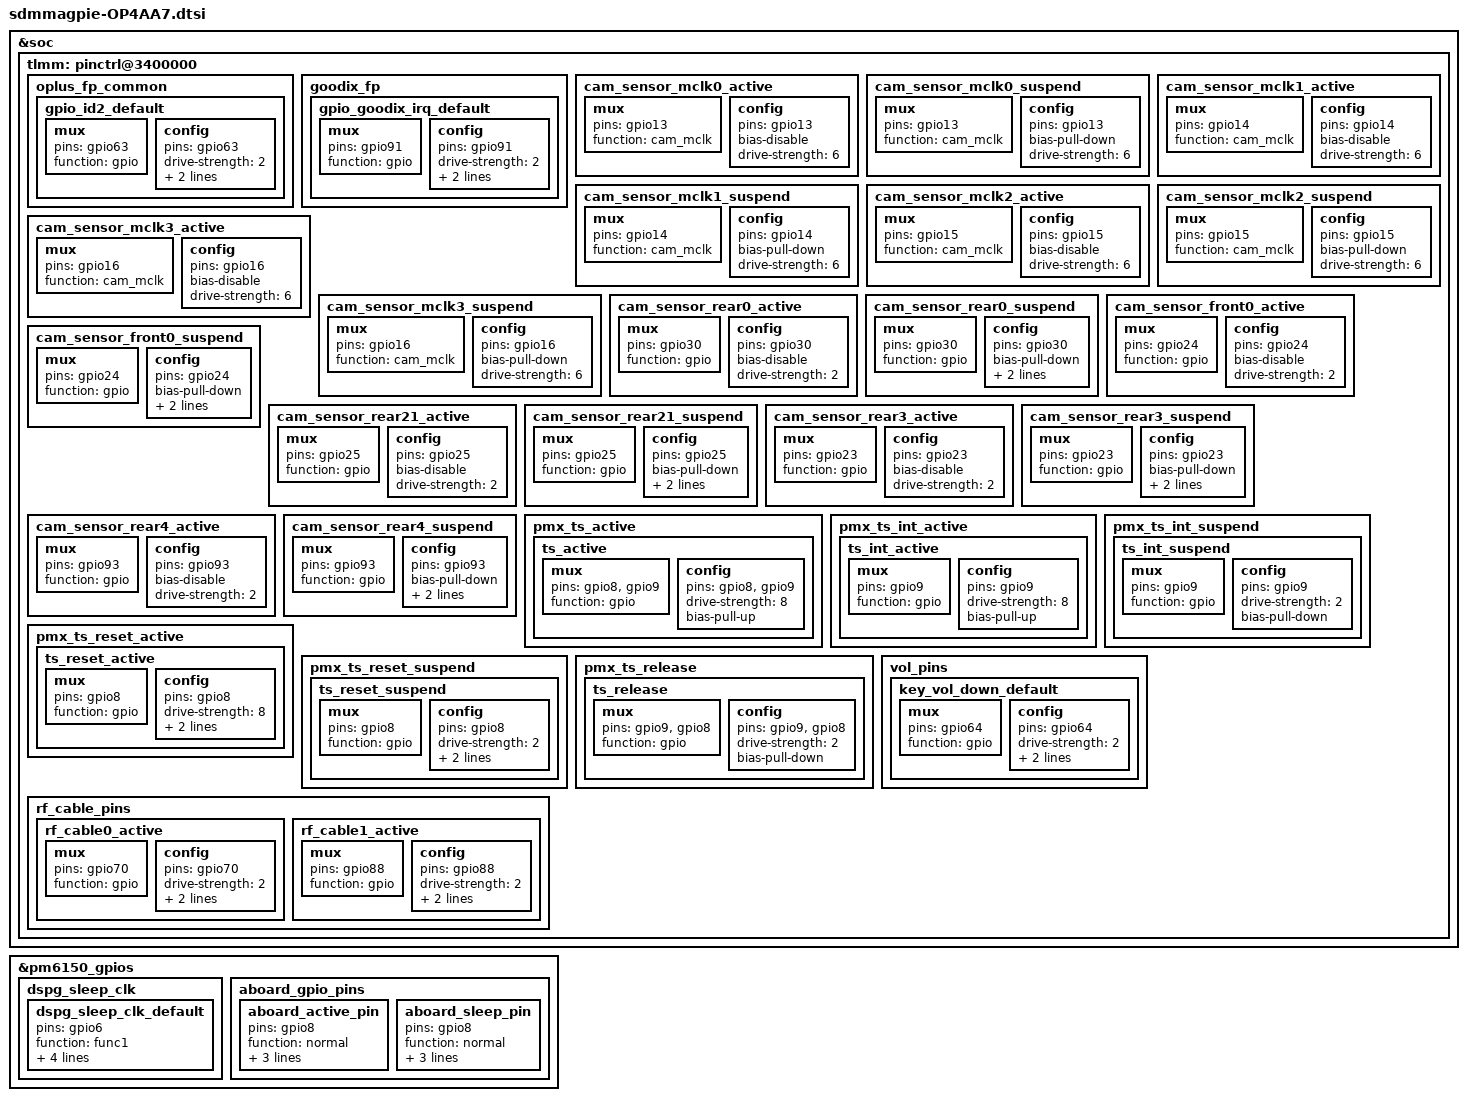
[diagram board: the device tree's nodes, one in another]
/* Copyright (c) 2018-2019, The Linux Foundation. All rights reserved.
 *
 * This program is free software; you can redistribute it and/or modify
 * it under the terms of the GNU General Public License version 2 and
 * only version 2 as published by the Free Software Foundation.
 *
 * This program is distributed in the hope that it will be useful,
 * but WITHOUT ANY WARRANTY; without even the implied warranty of
 * MERCHANTABILITY or FITNESS FOR A PARTICULAR PURPOSE.  See the
 * GNU General Public License for more details.
 */
#include <dt-bindings/gpio/gpio.h>
#include <dt-bindings/pinctrl/qcom,pmic-gpio.h>

&soc {
	tlmm: pinctrl@3400000 {
		oplus_fp_common{
			gpio_id2_default: gpio_id2_default {
				mux {
					pins = "gpio63";
					function = "gpio";
				};
				config {
					pins = "gpio63";
					drive-strength = <2>;
					bias-disable;
					input-enable;
				};
			};
		};

		goodix_fp{
			gpio_goodix_irq_default: gpio_goodix_irq_default {
				mux {
					pins = "gpio91";
					function = "gpio";
				};
				config {
					pins = "gpio91";
					drive-strength = <2>;
					bias-disable;
					input-enable;
				};
			};
		};

		cam_sensor_mclk0_active: cam_sensor_mclk0_active {
			/* MCLK0 */
			mux {
				pins = "gpio13";
				function = "cam_mclk";
			};

			config {
				pins = "gpio13";
				bias-disable; /* No PULL */
				drive-strength = <6>; /* 6 MA */
			};
		};

		cam_sensor_mclk0_suspend: cam_sensor_mclk0_suspend {
			/* MCLK0 */
			mux {
				pins = "gpio13";
				function = "cam_mclk";
			};

			config {
				pins = "gpio13";
				bias-pull-down; /* PULL DOWN */
				drive-strength = <6>; /* 6 MA */
			};
		};

		cam_sensor_mclk1_active: cam_sensor_mclk1_active {
			/* MCLK1 */
			mux {
				pins = "gpio14";
				function = "cam_mclk";
			};

			config {
				pins = "gpio14";
				bias-disable; /* No PULL */
				drive-strength = <6>; /* 6 MA */
			};
		};

		cam_sensor_mclk1_suspend: cam_sensor_mclk1_suspend {
			/* MCLK1 */
			mux {
				pins = "gpio14";
				function = "cam_mclk";
			};

			config {
				pins = "gpio14";
				bias-pull-down; /* PULL DOWN */
				drive-strength = <6>; /* 6 MA */
			};
		};

		cam_sensor_mclk2_active: cam_sensor_mclk2_active {
			/* MCLK2 */
			mux {
				pins = "gpio15";
				function = "cam_mclk";
			};

			config {
				pins = "gpio15";
				bias-disable; /* No PULL */
				drive-strength = <6>; /* 6 MA */
			};
		};

		cam_sensor_mclk2_suspend: cam_sensor_mclk2_suspend {
			/* MCLK2 */
			mux {
				pins = "gpio15";
				function = "cam_mclk";
			};

			config {
				pins = "gpio15";
				bias-pull-down; /* PULL DOWN */
				drive-strength = <6>; /* 6 MA */
			};
		};

		cam_sensor_mclk3_active: cam_sensor_mclk3_active {
			/* MCLK3 */
			mux {
				pins = "gpio16";
				function = "cam_mclk";
			};

			config {
				pins = "gpio16";
				bias-disable; /* No PULL */
				drive-strength = <6>; /* 6 MA */
			};
		};

		cam_sensor_mclk3_suspend: cam_sensor_mclk3_suspend {
			/* MCLK3 */
			mux {
				pins = "gpio16";
				function = "cam_mclk";
			};

			config {
				pins = "gpio16";
				bias-pull-down; /* PULL DOWN */
				drive-strength = <6>; /* 6 MA */
			};
		};
		cam_sensor_rear0_active: cam_sensor_rear0_active {
			/* RESET */
			mux {
				pins = "gpio30";
				function = "gpio";
			};

			config {
				pins = "gpio30";
				bias-disable; /* No PULL */
				drive-strength = <2>; /* 2 MA */
			};
		};

		cam_sensor_rear0_suspend: cam_sensor_rear0_suspend {
			/* RESET */
			mux {
				pins = "gpio30";
				function = "gpio";
			};

			config {
				pins = "gpio30";
				bias-pull-down; /* PULL DOWN */
				drive-strength = <2>; /* 2 MA */
				output-low;
			};
		};

		cam_sensor_front0_active: cam_sensor_front0_active {
			/* RESET  */
			mux {
				pins = "gpio24";
				function = "gpio";
			};

			config {
				pins = "gpio24";
				bias-disable; /* No PULL */
				drive-strength = <2>; /* 2 MA */
			};
		};

		cam_sensor_front0_suspend: cam_sensor_front0_suspend {
			/* RESET */
			mux {
				pins = "gpio24";
				function = "gpio";
			};

			config {
				pins = "gpio24";
				bias-pull-down; /* PULL DOWN */
				drive-strength = <2>; /* 2 MA */
				output-low;
			};
		};
		cam_sensor_rear21_active: cam_sensor_rear21_active {
			/* RESET */
			mux {
				pins = "gpio25";
				function = "gpio";
			};

			config {
				pins = "gpio25";
				bias-disable; /* No PULL */
				drive-strength = <2>; /* 2 MA */
			};
		};

		cam_sensor_rear21_suspend: cam_sensor_rear21_suspend {
			/* RESET */
			mux {
				pins = "gpio25";
				function = "gpio";
			};

			config {
				pins = "gpio25";
				bias-pull-down; /* PULL DOWN */
				drive-strength = <2>; /* 2 MA */
				output-low;
			};
		};
		cam_sensor_rear3_active: cam_sensor_rear3_active {
			/* RESET  */
			mux {
				pins = "gpio23";
				function = "gpio";
			};

			config {
				pins = "gpio23";
				bias-disable; /* No PULL */
				drive-strength = <2>; /* 2 MA */
			};
		};

		cam_sensor_rear3_suspend: cam_sensor_rear3_suspend {
			/* RESET */
			mux {
				pins = "gpio23";
				function = "gpio";
			};

			config {
				pins = "gpio23";
				bias-pull-down; /* PULL DOWN */
				drive-strength = <2>; /* 2 MA */
				output-low;
			};
		};
		cam_sensor_rear4_active: cam_sensor_rear4_active {
			/* RESET  */
			mux {
				pins = "gpio93";
				function = "gpio";
			};

			config {
				pins = "gpio93";
				bias-disable; /* No PULL */
				drive-strength = <2>; /* 2 MA */
			};
		};

		cam_sensor_rear4_suspend: cam_sensor_rear4_suspend {
			/* RESET */
			mux {
				pins = "gpio93";
				function = "gpio";
			};

			config {
				pins = "gpio93";
				bias-pull-down; /* PULL DOWN */
				drive-strength = <2>; /* 2 MA */
				output-low;
			};
		};

		pmx_ts_active {
			ts_active: ts_active {
				mux {
					pins = "gpio8", "gpio9";
					function = "gpio";
				};

				config {
					pins = "gpio8", "gpio9";
					drive-strength = <8>;
					bias-pull-up;
				};
			};
		};

		pmx_ts_int_active {
			ts_int_active: ts_int_active {
				mux {
					pins = "gpio9";
					function = "gpio";
				};

				config {
					pins = "gpio9";
					drive-strength = <8>;
					bias-pull-up;
				};
			};
		};

		pmx_ts_int_suspend {
			ts_int_suspend: ts_int_suspend {
				mux {
					pins = "gpio9";
					function = "gpio";
				};

				config {
					pins = "gpio9";
					drive-strength = <2>;
					bias-pull-down;
				};
			};
		};

		pmx_ts_reset_active {
			ts_reset_active: ts_reset_active {
				mux {
					pins = "gpio8";
					function = "gpio";
				};

				config {
					pins = "gpio8";
					drive-strength = <8>;
					input-disable;
					bias-disable;
				};
			};
		};

		pmx_ts_reset_suspend {
			ts_reset_suspend: ts_reset_suspend {
				mux {
					pins = "gpio8";
					function = "gpio";
				};

				config {
					pins = "gpio8";
					drive-strength = <2>;
					input-disable;
					bias-pull-down;
				};
			};
		};

		pmx_ts_release {
			ts_release: ts_release {
				mux {
					pins = "gpio9", "gpio8";
					function = "gpio";
				};

				config {
					pins = "gpio9", "gpio8";
					drive-strength = <2>;
					bias-pull-down;
				};
			};
		};
	};
};


&tlmm {
	vol_pins:vol_pins {
		key_vol_down_default:key_vol_down_default {
			mux {
				pins = "gpio64";
				function = "gpio";
			};

			config {
				pins = "gpio64";
				drive-strength = <2>;
				input-enable;
				bias-pull-up;
			};
		};
	};

	rf_cable_pins:rf_cable_pins {
		rf_cable0_active: rf_cable0_active {
			mux {
				pins = "gpio70";
				function = "gpio";
			};
			config {
				pins = "gpio70";
				drive-strength = <2>;
				input-enable;
				bias-pull-up;
			};
		};

		rf_cable1_active: rf_cable1_active {
			mux {
				pins = "gpio88";
				function = "gpio";
			};
			config {
				pins = "gpio88";
				drive-strength = <2>;
				input-enable;
				bias-pull-up;
			};
		};
	};
};

&pm6150_gpios {
	dspg_sleep_clk {
		dspg_sleep_clk_default: dspg_sleep_clk_default{
			pins = "gpio6";
			function = "func1"; /* Special Function 1 */
			bias-disable; /* No Pull */
			power-source = <0>; /* VIN0 */
			output-low; /* digital output, no invert */
			input-disable; /* prevent GPIO from being set to DIO */
		};
	};

	aboard_gpio_pins {
		aboard_active_pin:aboard_active_pin {
			pins = "gpio8";
			function = "normal";
			bias-pull-up; /* No Pull */
			power-source = <0>; /* VIN0 */
			input-enable;
		};

		aboard_sleep_pin:aboard_sleep_pin {
			pins = "gpio8";
			function = "normal";
			bias-high-impedance; /* No Pull */
			power-source = <0>; /* VIN0 */
			input-enable;
		};
	};
};
